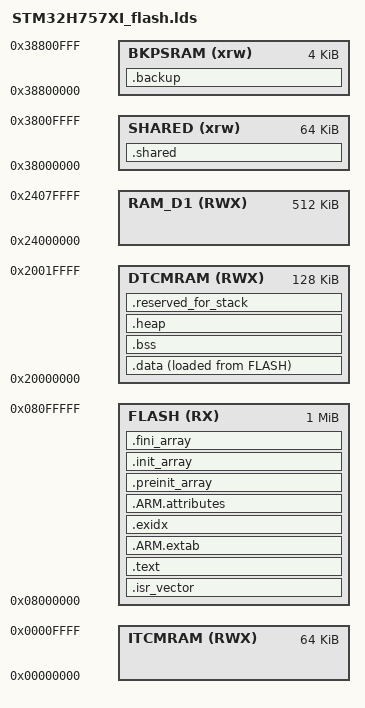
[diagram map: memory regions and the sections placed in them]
/* Generated by LinkerScriptGenerator [http://visualgdb.com/tools/LinkerScriptGenerator]
 * Target: STM32H757AI
 * The file is provided under the BSD license.
 */

ENTRY(Reset_Handler)

_Min_Heap_Size = 0xD000; /* required amount of heap  */

MEMORY
{
	FLASH (RX)		: ORIGIN = 0x08000000, LENGTH = 1M
	DTCMRAM (RWX)	: ORIGIN = 0x20000000, LENGTH = 128K
	ITCMRAM (RWX)	: ORIGIN = 0x00000000, LENGTH = 64K
	RAM_D1 (RWX)	: ORIGIN = 0x24000000, LENGTH = 512K
    SHARED (xrw)	: ORIGIN = 0x38000000, LENGTH = 64K  /* Shared SRAM4 0x38000000 - 0x3800FFFF */
    BKPSRAM (xrw)	: ORIGIN = 0x38800000, LENGTH = 4K   /* Backup SRAM4 0x38800000 - 0x38800FFF */
}

_estack = ORIGIN(DTCMRAM) + LENGTH(DTCMRAM); /* end of "DTCMRAM" Ram type memory */

SECTIONS
{
	.isr_vector :
	{
		. = ALIGN(4);
		KEEP(*(.isr_vector))
		. = ALIGN(4);
	} > FLASH

	.text :
	{
		. = ALIGN(4);
		_stext = .;

		*(.text)
		*(.text*)
		*(.rodata)
		*(.rodata*)
		*(.glue_7)
		*(.glue_7t)
		KEEP(*(.init))
		KEEP(*(.fini))
		. = ALIGN(4);
		_etext = .;

	} > FLASH

	.ARM.extab :
	{
		. = ALIGN(4);
		*(.ARM.extab)
		*(.gnu.linkonce.armextab.*)
		. = ALIGN(4);
	} > FLASH

	.exidx :
	{
		. = ALIGN(4);
		PROVIDE(__exidx_start = .);
		*(.ARM.exidx*)
		. = ALIGN(4);
		PROVIDE(__exidx_end = .);
	} > FLASH

	.ARM.attributes :
	{
		*(.ARM.attributes)
	} > FLASH

	.preinit_array :
	{
		PROVIDE(__preinit_array_start = .);
		KEEP(*(.preinit_array*))
		PROVIDE(__preinit_array_end = .);
	} > FLASH

	.init_array :
	{
		PROVIDE(__init_array_start = .);
		KEEP(*(SORT(.init_array.*)))
		KEEP(*(.init_array*))
		PROVIDE(__init_array_end = .);
	} > FLASH

	.fini_array :
	{
		PROVIDE(__fini_array_start = .);
		KEEP(*(.fini_array*))
		KEEP(*(SORT(.fini_array.*)))
		PROVIDE(__fini_array_end = .);
	} > FLASH

	.data :
	{
		. = ALIGN(4);
		_sdata = .;

		PROVIDE(__data_start__ = _sdata);
		*(.data)
		*(.data*)
		. = ALIGN(4);
		_edata = .;

		PROVIDE(__data_end__ = _edata);
	} > DTCMRAM AT >FLASH

	_sidata = LOADADDR(.data);

	.bss :
	{
		. = ALIGN(4);
		_sbss = .;

		PROVIDE(__bss_start__ = _sbss);
		KEEP(*(.bss))
		*(.bss*)
		*(COMMON)
		. = ALIGN(4);
		_ebss = .;

		PROVIDE(__bss_end__ = _ebss);
	} > DTCMRAM

	PROVIDE(end = .);

	.heap (NOLOAD) :
	{
		. = ALIGN(4);
		PROVIDE(__heap_start__ = .);
		KEEP(*(.heap))
		. = . + _Min_Heap_Size;
		. = ALIGN(4);
		PROVIDE(__heap_end__ = .);
	} > DTCMRAM

	_Stack_Size = _estack - .;
	.reserved_for_stack (NOLOAD) :
	{
		. = ALIGN(4);
		PROVIDE(__reserved_for_stack_start__ = .);
		KEEP(*(.reserved_for_stack))
		. = . + _Stack_Size;
		. = ALIGN(4);
		PROVIDE(__reserved_for_stack_end__ = .);
	} > DTCMRAM

	.backup(NOLOAD):
    {
	  . = ALIGN(4);
	  KEEP(*(.backup));
	  KEEP(*(.backup*));
	  . = ALIGN(4);
	} > BKPSRAM

	.shared :
	{
	  . = ALIGN(4);
	  KEEP(*(.shared));
	  KEEP(*(.shared*));
	  . = ALIGN(4);
	} > SHARED

}

